# ATSAME51J19A register map
Vendor: Microchip Technology; Series: SAME51; File version: 0
CPU: CM4 r0p1, little endian, MPU, FPU, 3 interrupt priority bits, 137 interrupts
Registers are 32-bit, read-write, reset 0x0 unless marked. A register's access mark holds for its fields unless they carry their own. Offsets are from the block's base; [hi:lo] are bit positions; {n}, {i} and the like mark numbered series; <NAME> marks a mode.

## ADC0 — Analog Digital Converter
Base 0x43001C00; register names take the prefix ADC_
Same registers: ADC1 0x43002000
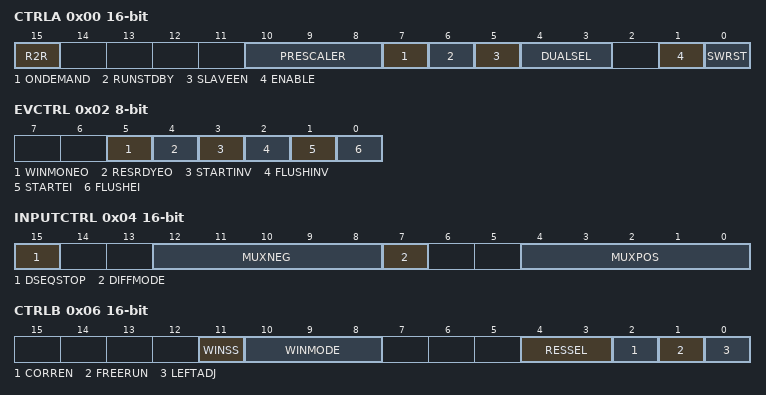
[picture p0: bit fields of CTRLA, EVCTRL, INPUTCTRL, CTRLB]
0x00 CTRLA 16-bit — Control A
  [15] R2R — Rail to Rail Operation Enable
  [10:8] PRESCALER — Prescaler Configuration
    0=DIV2 (Peripheral clock divided by 2); 1=DIV4 (Peripheral clock divided by 4); 2=DIV8 (Peripheral clock divided by 8); 3=DIV16 (Peripheral clock divided by 16); 4=DIV32 (Peripheral clock divided by 32); 5=DIV64 (Peripheral clock divided by 64); 6=DIV128 (Peripheral clock divided by 128); 7=DIV256 (Peripheral clock divided by 256)
  [7] ONDEMAND — On Demand Control
  [6] RUNSTDBY — Run in Standby
  [5] SLAVEEN — Slave Enable
  [4:3] DUALSEL — Dual Mode Trigger Selection
    0=BOTH (Start event or software trigger will start a conversion on both ADCs); 1=INTERLEAVE (START event or software trigger will alternatingly start a conversion on ADC0 and ADC1)
  [1] ENABLE
  [0] SWRST — Software Reset
0x02 EVCTRL 8-bit — Event Control
  [5] WINMONEO — Window Monitor Event Out
  [4] RESRDYEO — Result Ready Event Out
  [3] STARTINV — Start Conversion Event Invert Enable
  [2] FLUSHINV — Flush Event Invert Enable
  [1] STARTEI — Start Conversion Event Input Enable
  [0] FLUSHEI — Flush Event Input Enable
0x03 DBGCTRL 8-bit — Debug Control
  [0] DBGRUN — Debug Run
0x04 INPUTCTRL 16-bit — Input Control
  [15] DSEQSTOP — Stop DMA Sequencing
  [12:8] MUXNEG — Negative Mux Input Selection
    {v}=AIN{v} (ADC AIN{v} Pin) (v=0..7); 24=GND (Internal Ground)
  [7] DIFFMODE — Differential Mode
  [4:0] MUXPOS — Positive Mux Input Selection
    {v}=AIN{v} (ADC AIN{v} Pin) (v=0..15); 24=SCALEDCOREVCC (1/4 Scaled Core Supply); 25=SCALEDVBAT (1/4 Scaled VBAT Supply); 26=SCALEDIOVCC (1/4 Scaled I/O Supply); 27=BANDGAP (Bandgap Voltage); 28=PTAT (Temperature Sensor TSENSP); 29=CTAT (Temperature Sensor TSENSC); 30=DAC (DAC Output); 31=PTC (PTC output (only on ADC0))
0x06 CTRLB 16-bit — Control B
  [11] WINSS — Window Single Sample
  [10:8] WINMODE — Window Monitor Mode
    0=DISABLE (No window mode (default)); 1=MODE1 (RESULT > WINLT); 2=MODE2 (RESULT < WINUT); 3=MODE3 (WINLT < RESULT < WINUT); 4=MODE4 (!(WINLT < RESULT < WINUT))
  [4:3] RESSEL — Conversion Result Resolution
    0=12BIT (12-bit result); 1=16BIT (For averaging mode output); 2=10BIT (10-bit result); 3=8BIT (8-bit result)
  [2] CORREN — Digital Correction Logic Enable
  [1] FREERUN — Free Running Mode
  [0] LEFTADJ — Left-Adjusted Result
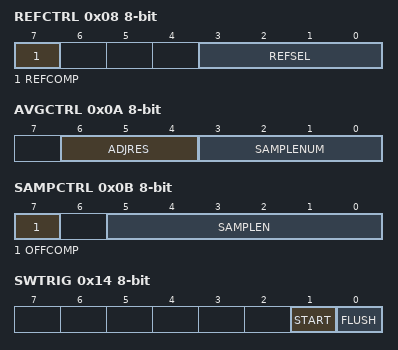
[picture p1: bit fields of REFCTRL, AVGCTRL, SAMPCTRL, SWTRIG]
0x08 REFCTRL 8-bit — Reference Control
  [7] REFCOMP — Reference Buffer Offset Compensation Enable
  [3:0] REFSEL — Reference Selection
    0=INTREF (Internal Bandgap Reference); 2=INTVCC0 (1/2 VDDANA); 3=INTVCC1 (VDDANA); 4=AREFA (External Reference A); 5=AREFB (External Reference B); 6=AREFC (External Reference C (only on ADC1))
0x0A AVGCTRL 8-bit — Average Control
  [6:4] ADJRES — Adjusting Result / Division Coefficient
  [3:0] SAMPLENUM — Number of Samples to be Collected
    0=1 sample; 1=2 samples; 2=4 samples; 3=8 samples; 4=16 samples; 5=32 samples; 6=64 samples; 7=128 samples; 8=256 samples; 9=512 samples; 10=1024 samples
0x0B SAMPCTRL 8-bit — Sample Time Control
  [7] OFFCOMP — Comparator Offset Compensation Enable
  [5:0] SAMPLEN — Sampling Time Length
0x0C WINLT 16-bit — Window Monitor Lower Threshold
  [15:0] WINLT — Window Lower Threshold
0x0E WINUT 16-bit — Window Monitor Upper Threshold
  [15:0] WINUT — Window Upper Threshold
0x10 GAINCORR 16-bit — Gain Correction
  [11:0] GAINCORR — Gain Correction Value
0x12 OFFSETCORR 16-bit — Offset Correction
  [11:0] OFFSETCORR — Offset Correction Value
0x14 SWTRIG 8-bit — Software Trigger
  [1] START — Start ADC Conversion
  [0] FLUSH — ADC Conversion Flush
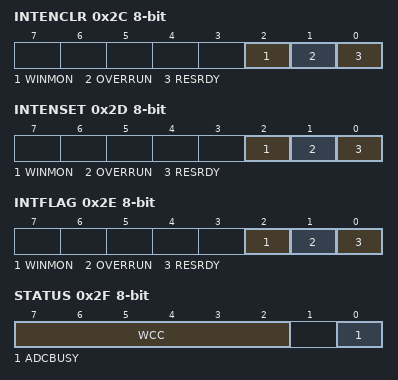
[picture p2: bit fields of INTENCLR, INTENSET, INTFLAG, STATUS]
0x2C INTENCLR 8-bit write-1-clears — Interrupt Enable Clear
  [2] WINMON — Window Monitor Interrupt Disable
  [1] OVERRUN — Overrun Interrupt Disable
  [0] RESRDY — Result Ready Interrupt Disable
0x2D INTENSET 8-bit write-1-sets — Interrupt Enable Set
  [2] WINMON — Window Monitor Interrupt Enable
  [1] OVERRUN — Overrun Interrupt Enable
  [0] RESRDY — Result Ready Interrupt Enable
0x2E INTFLAG 8-bit write-1-clears — Interrupt Flag Status and Clear
  [2] WINMON — Window Monitor Interrupt Flag
  [1] OVERRUN — Overrun Interrupt Flag
  [0] RESRDY — Result Ready Interrupt Flag
0x2F STATUS 8-bit ro
  [7:2] WCC — Window Comparator Counter
  [0] ADCBUSY — ADC Busy Status
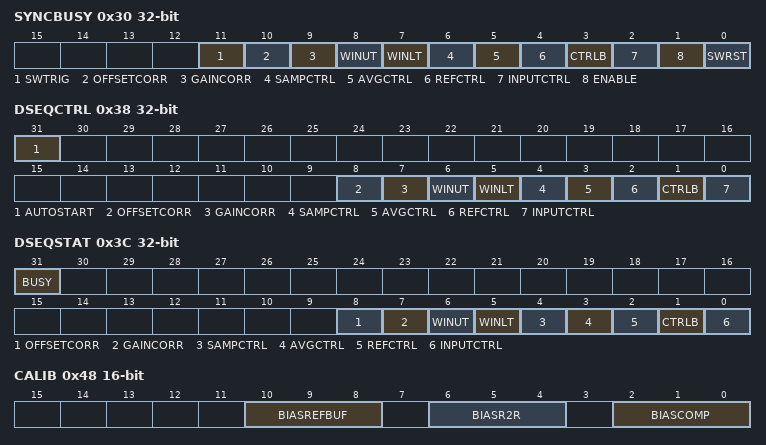
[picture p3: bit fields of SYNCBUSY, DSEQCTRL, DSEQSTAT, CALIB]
0x30 SYNCBUSY ro — Synchronization Busy
  [11] SWTRIG — Software Trigger Synchronization Busy
  [10] OFFSETCORR — Offset Correction Synchronization Busy
  [9] GAINCORR — Gain Correction Synchronization Busy
  [8] WINUT — Window Monitor Upper Threshold Synchronization Busy
  [7] WINLT — Window Monitor Lower Threshold Synchronization Busy
  [6] SAMPCTRL — Sampling Time Control Synchronization Busy
  [5] AVGCTRL — Average Control Synchronization Busy
  [4] REFCTRL — Reference Control Synchronization Busy
  [3] CTRLB — Control B Synchronization Busy
  [2] INPUTCTRL — Input Control Synchronization Busy
  [1] ENABLE — ENABLE Synchronization Busy
  [0] SWRST — SWRST Synchronization Busy
0x34 DSEQDATA wo — DMA Sequencial Data
  [31:0] DATA — DMA Sequential Data
0x38 DSEQCTRL — DMA Sequential Control
  [31] AUTOSTART — ADC Auto-Start Conversion
  [8] OFFSETCORR — Offset Correction
  [7] GAINCORR — Gain Correction
  [6] WINUT — Window Monitor Upper Threshold
  [5] WINLT — Window Monitor Lower Threshold
  [4] SAMPCTRL — Sampling Time Control
  [3] AVGCTRL — Average Control
  [2] REFCTRL — Reference Control
  [1] CTRLB — Control B
  [0] INPUTCTRL — Input Control
0x3C DSEQSTAT ro — DMA Sequencial Status
  [31] BUSY — DMA Sequencing Busy
  [8] OFFSETCORR — Offset Correction
  [7] GAINCORR — Gain Correction
  [6] WINUT — Window Monitor Upper Threshold
  [5] WINLT — Window Monitor Lower Threshold
  [4] SAMPCTRL — Sampling Time Control
  [3] AVGCTRL — Average Control
  [2] REFCTRL — Reference Control
  [1] CTRLB — Control B
  [0] INPUTCTRL — Input Control
0x40 RESULT 16-bit ro — Result Conversion Value
0x44 RESS 16-bit ro — Last Sample Result
  [15:0] RESS — Last ADC conversion result
0x48 CALIB 16-bit — Calibration
  [10:8] BIASREFBUF — Bias Reference Buffer Scaling
  [6:4] BIASR2R — Bias R2R Ampli scaling
  [2:0] BIASCOMP — Bias Comparator Scaling

## Notices in the file
Copyright (c) 2026 Microchip Technology Inc.
SPDX-License-Identifier: Apache-2.0
Licensed under the Apache License, Version 2.0 (the "License");
you may not use this file except in compliance with the License.
You may obtain a copy of the License at
http://www.apache.org/licenses/LICENSE-2.0
Unless required by applicable law or agreed to in writing, software
distributed under the License is distributed on an "AS IS" BASIS,
WITHOUT WARRANTIES OR CONDITIONS OF ANY KIND, either express or implied.
See the License for the specific language governing permissions and
limitations under the License.
